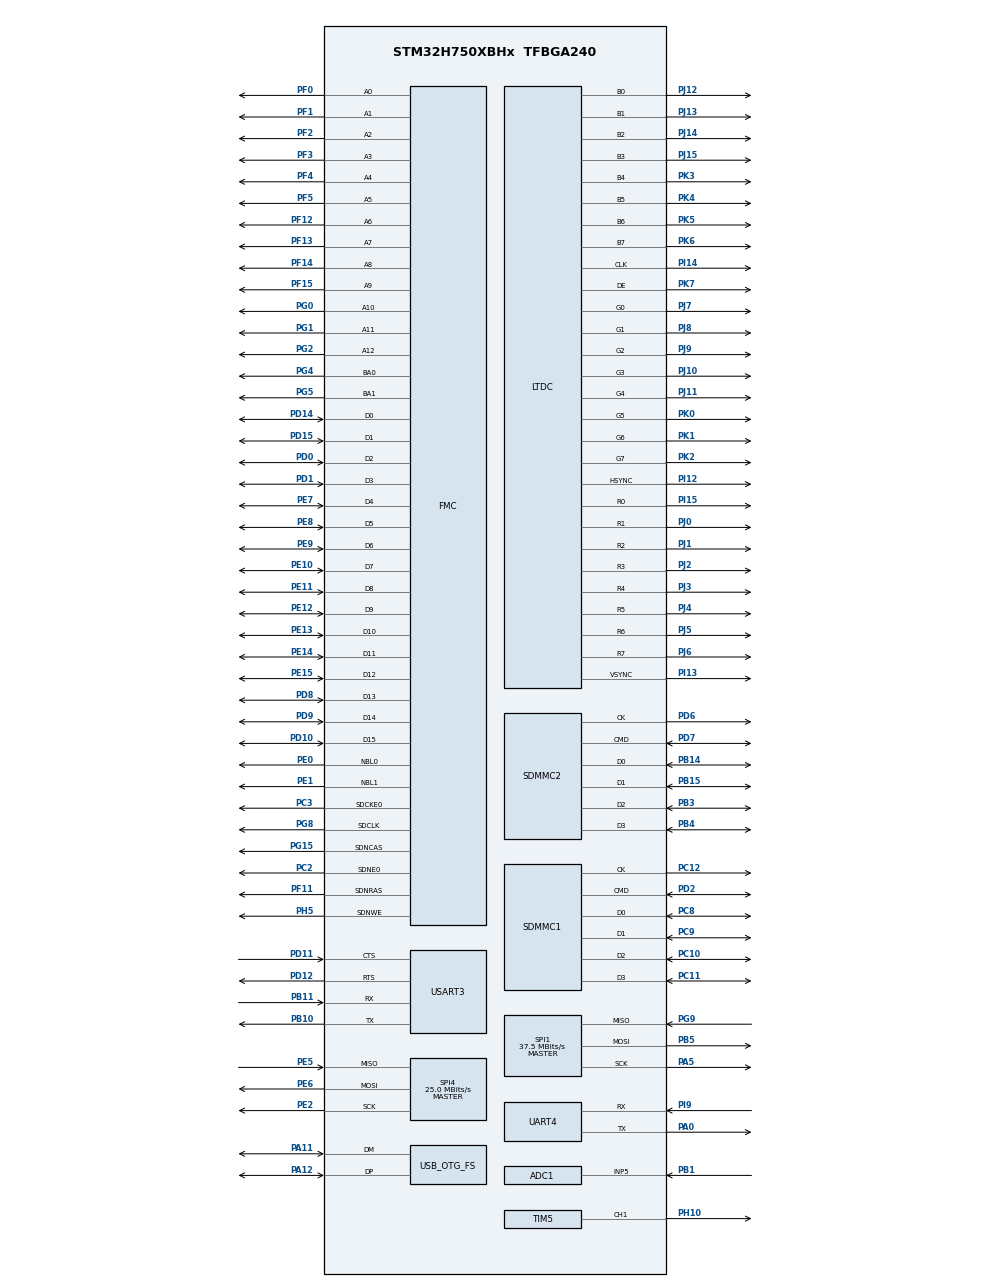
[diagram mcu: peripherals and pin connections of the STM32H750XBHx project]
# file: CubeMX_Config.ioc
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ADC1.Channel-0\#ChannelRegularConversion=ADC_CHANNEL_5
ADC1.NbrOfConversionFlag=1
ADC1.OffsetNumber-0\#ChannelRegularConversion=ADC_OFFSET_NONE
ADC1.OffsetSignedSaturation-0\#ChannelRegularConversion=DISABLE
ADC1.Rank-0\#ChannelRegularConversion=1
ADC1.SamplingTime-0\#ChannelRegularConversion=ADC_SAMPLETIME_1CYCLE_5
ADC1.master=1
Mcu.Family=STM32H7
Mcu.Name=STM32H750XBHx
Mcu.Package=TFBGA240
NVIC.OTG_FS_IRQn=true\:0\:0\:false\:false\:true\:true\:true\:true
NVIC.PriorityGroup=NVIC_PRIORITYGROUP_4
NVIC.SDMMC1_IRQn=true\:0\:0\:false\:false\:true\:true\:true\:true
NVIC.SDMMC2_IRQn=true\:0\:0\:false\:false\:true\:true\:true\:true
PA0.Mode=Asynchronous
PA0.Signal=UART4_TX
PA11.GPIO_Speed=GPIO_SPEED_FREQ_VERY_HIGH
PA11.Mode=Device_Only
PA11.Signal=USB_OTG_FS_DM
PA12.GPIO_Speed=GPIO_SPEED_FREQ_VERY_HIGH
PA12.Mode=Device_Only
PA12.Signal=USB_OTG_FS_DP
PA5.GPIO_Speed=GPIO_SPEED_FREQ_HIGH
PA5.Mode=Full_Duplex_Master
PA5.Signal=SPI1_SCK
PB1.Signal=ADCx_INP5
PB10.Mode=Asynchronous
PB10.Signal=USART3_TX
PB11.Mode=Asynchronous
PB11.Signal=USART3_RX
PB14.Mode=SD_4_bits_Wide_bus
PB14.Signal=SDMMC2_D0
PB15.Mode=SD_4_bits_Wide_bus
PB15.Signal=SDMMC2_D1
PB3\ (JTDO/TRACESWO).Mode=SD_4_bits_Wide_bus
PB3\ (JTDO/TRACESWO).Signal=SDMMC2_D2
PB4\ (NJTRST).Mode=SD_4_bits_Wide_bus
PB4\ (NJTRST).Signal=SDMMC2_D3
PB5.GPIO_Speed=GPIO_SPEED_FREQ_HIGH
PB5.Mode=Full_Duplex_Master
PB5.Signal=SPI1_MOSI
PC10.Mode=SD_4_bits_Wide_bus
PC10.Signal=SDMMC1_D2
PC11.Mode=SD_4_bits_Wide_bus
PC11.Signal=SDMMC1_D3
PC12.Mode=SD_4_bits_Wide_bus
PC12.Signal=SDMMC1_CK
PC2.GPIO_Speed_High_Default=GPIO_SPEED_FREQ_VERY_HIGH
PC2.Mode=SdramChipSelect1_1
PC2.Signal=FMC_SDNE0
PC3.GPIO_Speed_High_Default=GPIO_SPEED_FREQ_VERY_HIGH
PC3.Mode=SdramChipSelect1_1
PC3.Signal=FMC_SDCKE0
PC8.Mode=SD_4_bits_Wide_bus
PC8.Signal=SDMMC1_D0
PC9.Mode=SD_4_bits_Wide_bus
PC9.Signal=SDMMC1_D1
PD0.GPIO_Speed_High_Default=GPIO_SPEED_FREQ_VERY_HIGH
PD0.Signal=FMC_D2_DA2
PD1.GPIO_Speed_High_Default=GPIO_SPEED_FREQ_VERY_HIGH
PD1.Signal=FMC_D3_DA3
PD10.GPIO_Speed_High_Default=GPIO_SPEED_FREQ_VERY_HIGH
PD10.Signal=FMC_D15_DA15
PD11.Mode=CTS_RTS
PD11.Signal=USART3_CTS
PD12.Mode=CTS_RTS
PD12.Signal=USART3_RTS
PD14.GPIO_Speed_High_Default=GPIO_SPEED_FREQ_VERY_HIGH
PD14.Signal=FMC_D0_DA0
PD15.GPIO_Speed_High_Default=GPIO_SPEED_FREQ_VERY_HIGH
PD15.Signal=FMC_D1_DA1
PD2.Mode=SD_4_bits_Wide_bus
PD2.Signal=SDMMC1_CMD
PD6.Mode=SD_4_bits_Wide_bus
PD6.Signal=SDMMC2_CK
PD7.Mode=SD_4_bits_Wide_bus
PD7.Signal=SDMMC2_CMD
PD8.GPIO_Speed_High_Default=GPIO_SPEED_FREQ_VERY_HIGH
PD8.Signal=FMC_D13_DA13
PD9.GPIO_Speed_High_Default=GPIO_SPEED_FREQ_VERY_HIGH
PD9.Signal=FMC_D14_DA14
PE0.GPIO_Speed_High_Default=GPIO_SPEED_FREQ_VERY_HIGH
PE0.Signal=FMC_NBL0
PE1.GPIO_Speed_High_Default=GPIO_SPEED_FREQ_VERY_HIGH
PE1.Signal=FMC_NBL1
PE10.GPIO_Speed_High_Default=GPIO_SPEED_FREQ_VERY_HIGH
PE10.Signal=FMC_D7_DA7
PE11.GPIO_Speed_High_Default=GPIO_SPEED_FREQ_VERY_HIGH
PE11.Signal=FMC_D8_DA8
PE12.GPIO_Speed_High_Default=GPIO_SPEED_FREQ_VERY_HIGH
PE12.Signal=FMC_D9_DA9
PE13.GPIO_Speed_High_Default=GPIO_SPEED_FREQ_VERY_HIGH
PE13.Signal=FMC_D10_DA10
PE14.GPIO_Speed_High_Default=GPIO_SPEED_FREQ_VERY_HIGH
PE14.Signal=FMC_D11_DA11
PE15.GPIO_Speed_High_Default=GPIO_SPEED_FREQ_VERY_HIGH
PE15.Signal=FMC_D12_DA12
PE2.GPIO_Speed=GPIO_SPEED_FREQ_HIGH
PE2.Mode=Full_Duplex_Master
PE2.Signal=SPI4_SCK
PE5.GPIO_Speed=GPIO_SPEED_FREQ_HIGH
PE5.Mode=Full_Duplex_Master
PE5.Signal=SPI4_MISO
PE6.GPIO_Speed=GPIO_SPEED_FREQ_HIGH
PE6.Mode=Full_Duplex_Master
PE6.Signal=SPI4_MOSI
PE7.GPIO_Speed_High_Default=GPIO_SPEED_FREQ_VERY_HIGH
PE7.Signal=FMC_D4_DA4
PE8.GPIO_Speed_High_Default=GPIO_SPEED_FREQ_VERY_HIGH
PE8.Signal=FMC_D5_DA5
PE9.GPIO_Speed_High_Default=GPIO_SPEED_FREQ_VERY_HIGH
PE9.Signal=FMC_D6_DA6
PF0.GPIO_Speed_High_Default=GPIO_SPEED_FREQ_VERY_HIGH
PF0.Signal=FMC_A0
PF1.GPIO_Speed_High_Default=GPIO_SPEED_FREQ_VERY_HIGH
PF1.Signal=FMC_A1
PF11.GPIO_Speed_High_Default=GPIO_SPEED_FREQ_VERY_HIGH
PF11.Signal=FMC_SDNRAS
PF12.GPIO_Speed_High_Default=GPIO_SPEED_FREQ_VERY_HIGH
PF12.Signal=FMC_A6
PF13.GPIO_Speed_High_Default=GPIO_SPEED_FREQ_VERY_HIGH
PF13.Signal=FMC_A7
PF14.GPIO_Speed_High_Default=GPIO_SPEED_FREQ_VERY_HIGH
PF14.Signal=FMC_A8
PF15.GPIO_Speed_High_Default=GPIO_SPEED_FREQ_VERY_HIGH
PF15.Signal=FMC_A9
PF2.GPIO_Speed_High_Default=GPIO_SPEED_FREQ_VERY_HIGH
PF2.Signal=FMC_A2
PF3.GPIO_Speed_High_Default=GPIO_SPEED_FREQ_VERY_HIGH
PF3.Signal=FMC_A3
PF4.GPIO_Speed_High_Default=GPIO_SPEED_FREQ_VERY_HIGH
PF4.Signal=FMC_A4
PF5.GPIO_Speed_High_Default=GPIO_SPEED_FREQ_VERY_HIGH
PF5.Signal=FMC_A5
PG0.GPIO_Speed_High_Default=GPIO_SPEED_FREQ_VERY_HIGH
PG0.Signal=FMC_A10
PG1.GPIO_Speed_High_Default=GPIO_SPEED_FREQ_VERY_HIGH
PG1.Signal=FMC_A11
PG11.GPIO_Speed=GPIO_SPEED_FREQ_VERY_HIGH
PG11.Signal=ETH_TX_EN
PG14.GPIO_Speed=GPIO_SPEED_FREQ_VERY_HIGH
PG14.Signal=ETH_TXD1
PG15.GPIO_Speed_High_Default=GPIO_SPEED_FREQ_VERY_HIGH
PG15.Signal=FMC_SDNCAS
PG2.GPIO_Speed_High_Default=GPIO_SPEED_FREQ_VERY_HIGH
PG2.Signal=FMC_A12
PG4.GPIO_Speed_High_Default=GPIO_SPEED_FREQ_VERY_HIGH
PG4.Signal=FMC_A14_BA0
PG5.GPIO_Speed_High_Default=GPIO_SPEED_FREQ_VERY_HIGH
PG5.Signal=FMC_A15_BA1
PG8.GPIO_Speed_High_Default=GPIO_SPEED_FREQ_VERY_HIGH
PG8.Signal=FMC_SDCLK
PG9.GPIO_Speed=GPIO_SPEED_FREQ_HIGH
PG9.Mode=Full_Duplex_Master
PG9.Signal=SPI1_MISO
PH0-OSC_IN\ (PH0).Mode=HSE-External-Oscillator
PH0-OSC_IN\ (PH0).Signal=RCC_OSC_IN
PH1-OSC_OUT\ (PH1).Mode=HSE-External-Oscillator
PH1-OSC_OUT\ (PH1).Signal=RCC_OSC_OUT
PH10.Signal=S_TIM5_CH1
PH5.GPIO_Speed_High_Default=GPIO_SPEED_FREQ_VERY_HIGH
PH5.Signal=FMC_SDNWE
PI12.GPIO_Speed=GPIO_SPEED_FREQ_VERY_HIGH
PI12.Mode=RGB888
PI12.Signal=LTDC_HSYNC
PI13.GPIO_Speed=GPIO_SPEED_FREQ_VERY_HIGH
PI13.Mode=RGB888
PI13.Signal=LTDC_VSYNC
PI14.GPIO_Speed=GPIO_SPEED_FREQ_VERY_HIGH
PI14.Mode=RGB888
PI14.Signal=LTDC_CLK
PI15.GPIO_Speed=GPIO_SPEED_FREQ_VERY_HIGH
PI15.Mode=RGB888
PI15.Signal=LTDC_R0
PI9.Mode=Asynchronous
PI9.Signal=UART4_RX
PJ0.GPIO_Speed=GPIO_SPEED_FREQ_VERY_HIGH
PJ0.Mode=RGB888
PJ0.Signal=LTDC_R1
PJ1.GPIO_Speed=GPIO_SPEED_FREQ_VERY_HIGH
PJ1.Mode=RGB888
PJ1.Signal=LTDC_R2
PJ10.GPIO_Speed=GPIO_SPEED_FREQ_VERY_HIGH
PJ10.Mode=RGB888
PJ10.Signal=LTDC_G3
PJ11.GPIO_Speed=GPIO_SPEED_FREQ_VERY_HIGH
PJ11.Mode=RGB888
PJ11.Signal=LTDC_G4
PJ12.GPIO_Speed=GPIO_SPEED_FREQ_VERY_HIGH
PJ12.Mode=RGB888
PJ12.Signal=LTDC_B0
PJ13.GPIO_Speed=GPIO_SPEED_FREQ_VERY_HIGH
PJ13.Mode=RGB888
PJ13.Signal=LTDC_B1
PJ14.GPIO_Speed=GPIO_SPEED_FREQ_VERY_HIGH
PJ14.Mode=RGB888
PJ14.Signal=LTDC_B2
PJ15.GPIO_Speed=GPIO_SPEED_FREQ_VERY_HIGH
PJ15.Mode=RGB888
PJ15.Signal=LTDC_B3
PJ2.GPIO_Speed=GPIO_SPEED_FREQ_VERY_HIGH
PJ2.Mode=RGB888
PJ2.Signal=LTDC_R3
PJ3.GPIO_Speed=GPIO_SPEED_FREQ_VERY_HIGH
PJ3.Mode=RGB888
PJ3.Signal=LTDC_R4
PJ4.GPIO_Speed=GPIO_SPEED_FREQ_VERY_HIGH
PJ4.Mode=RGB888
PJ4.Signal=LTDC_R5
PJ5.GPIO_Speed=GPIO_SPEED_FREQ_VERY_HIGH
PJ5.Mode=RGB888
PJ5.Signal=LTDC_R6
PJ6.GPIO_Speed=GPIO_SPEED_FREQ_VERY_HIGH
PJ6.Mode=RGB888
PJ6.Signal=LTDC_R7
PJ7.GPIO_Speed=GPIO_SPEED_FREQ_VERY_HIGH
PJ7.Mode=RGB888
PJ7.Signal=LTDC_G0
PJ8.GPIO_Speed=GPIO_SPEED_FREQ_VERY_HIGH
PJ8.Mode=RGB888
PJ8.Signal=LTDC_G1
PJ9.GPIO_Speed=GPIO_SPEED_FREQ_VERY_HIGH
PJ9.Mode=RGB888
PJ9.Signal=LTDC_G2
PK0.GPIO_Speed=GPIO_SPEED_FREQ_VERY_HIGH
PK0.Mode=RGB888
PK0.Signal=LTDC_G5
PK1.GPIO_Speed=GPIO_SPEED_FREQ_VERY_HIGH
PK1.Mode=RGB888
PK1.Signal=LTDC_G6
PK2.GPIO_Speed=GPIO_SPEED_FREQ_VERY_HIGH
PK2.Mode=RGB888
PK2.Signal=LTDC_G7
PK3.GPIO_Speed=GPIO_SPEED_FREQ_VERY_HIGH
PK3.Mode=RGB888
PK3.Signal=LTDC_B4
PK4.GPIO_Speed=GPIO_SPEED_FREQ_VERY_HIGH
PK4.Mode=RGB888
PK4.Signal=LTDC_B5
PK5.GPIO_Speed=GPIO_SPEED_FREQ_VERY_HIGH
PK5.Mode=RGB888
PK5.Signal=LTDC_B6
PK6.GPIO_Speed=GPIO_SPEED_FREQ_VERY_HIGH
PK6.Mode=RGB888
PK6.Signal=LTDC_B7
PK7.GPIO_Speed=GPIO_SPEED_FREQ_VERY_HIGH
PK7.Mode=RGB888
PK7.Signal=LTDC_DE
ProjectManager.HeapSize=0x200
ProjectManager.StackSize=0x400
ProjectManager.TargetToolchain=Makefile
RCC.ADCFreq_Value=75000000
RCC.APB1Freq_Value=18750000
RCC.APB2Freq_Value=18750000
RCC.APB3Freq_Value=18750000
RCC.APB4Freq_Value=18750000
RCC.CortexFreq_Value=75000000
RCC.D1PPRE=RCC_APB3_DIV2
RCC.D2PPRE1=RCC_APB1_DIV2
RCC.D2PPRE2=RCC_APB2_DIV2
RCC.D3PPRE=RCC_APB4_DIV2
RCC.DIVM1=2
RCC.DIVM2=2
RCC.DIVM3=2
RCC.DIVN1=12
RCC.DIVN2=12
RCC.DIVN3=12
RCC.DIVP3=8
RCC.DIVQ3=3
RCC.DIVR3=3
RCC.FMCCLockSelection=RCC_FMCCLKSOURCE_PLL2
RCC.HCLKFreq_Value=37500000
RCC.HPRE=RCC_HCLK_DIV2
RCC.LPTIM1CLockSelection=RCC_LPTIM1CLKSOURCE_LSI
RCC.PLL2FRACN=0
RCC.PLL3FRACN=0
RCC.PLLFRACN=0
RCC.PLLSourceVirtual=RCC_PLLSOURCE_HSE
RCC.SDMMC1CLockSelection=RCC_SDMMCCLKSOURCE_PLL2
RCC.SPI123CLockSelection=RCC_SPI123CLKSOURCE_PLL2
RCC.SYSCLKFreq_VALUE=75000000
RCC.SYSCLKSource=RCC_SYSCLKSOURCE_PLLCLK
RCC.Spi45ClockSelection=RCC_SPI45CLKSOURCE_PLL3
RCC.USBCLockSelection=RCC_USBCLKSOURCE_HSI48
RCC.USBFreq_Value=48000000
SH.ADCx_INP5.0=ADC1_INP5,IN5-Single-Ended
SH.FMC_A0.0=FMC_A0,13b-sda1
SH.FMC_A1.0=FMC_A1,13b-sda1
SH.FMC_A10.0=FMC_A10,13b-sda1
SH.FMC_A11.0=FMC_A11,13b-sda1
SH.FMC_A12.0=FMC_A12,13b-sda1
SH.FMC_A14_BA0.0=FMC_BA0,FourSdramBanks1
SH.FMC_A15_BA1.0=FMC_BA1,FourSdramBanks1
SH.FMC_A2.0=FMC_A2,13b-sda1
SH.FMC_A3.0=FMC_A3,13b-sda1
SH.FMC_A4.0=FMC_A4,13b-sda1
SH.FMC_A5.0=FMC_A5,13b-sda1
SH.FMC_A6.0=FMC_A6,13b-sda1
SH.FMC_A7.0=FMC_A7,13b-sda1
SH.FMC_A8.0=FMC_A8,13b-sda1
SH.FMC_A9.0=FMC_A9,13b-sda1
SH.FMC_D0_DA0.0=FMC_D0,sd-16b-d1
SH.FMC_D10_DA10.0=FMC_D10,sd-16b-d1
SH.FMC_D11_DA11.0=FMC_D11,sd-16b-d1
SH.FMC_D12_DA12.0=FMC_D12,sd-16b-d1
SH.FMC_D13_DA13.0=FMC_D13,sd-16b-d1
SH.FMC_D14_DA14.0=FMC_D14,sd-16b-d1
SH.FMC_D15_DA15.0=FMC_D15,sd-16b-d1
SH.FMC_D1_DA1.0=FMC_D1,sd-16b-d1
SH.FMC_D2_DA2.0=FMC_D2,sd-16b-d1
SH.FMC_D3_DA3.0=FMC_D3,sd-16b-d1
SH.FMC_D4_DA4.0=FMC_D4,sd-16b-d1
SH.FMC_D5_DA5.0=FMC_D5,sd-16b-d1
SH.FMC_D6_DA6.0=FMC_D6,sd-16b-d1
SH.FMC_D7_DA7.0=FMC_D7,sd-16b-d1
SH.FMC_D8_DA8.0=FMC_D8,sd-16b-d1
SH.FMC_D9_DA9.0=FMC_D9,sd-16b-d1
SH.FMC_NBL0.0=FMC_NBL0,Sd2ByteEnable1
SH.FMC_NBL1.0=FMC_NBL1,Sd2ByteEnable1
SH.FMC_SDCLK.0=FMC_SDCLK,13b-sda1
SH.FMC_SDNCAS.0=FMC_SDNCAS,13b-sda1
SH.FMC_SDNRAS.0=FMC_SDNRAS,13b-sda1
SH.FMC_SDNWE.0=FMC_SDNWE,13b-sda1
SH.S_TIM5_CH1.0=TIM5_CH1,PWM Generation1 CH1
SPI1.BaudRatePrescaler=SPI_BAUDRATEPRESCALER_2
SPI1.CalculateBaudRate=37.5 MBits/s
SPI1.Direction=SPI_DIRECTION_2LINES
SPI1.Mode=SPI_MODE_MASTER
SPI1.VirtualType=VM_MASTER
SPI4.BaudRatePrescaler=SPI_BAUDRATEPRESCALER_2
SPI4.CalculateBaudRate=25.0 MBits/s
SPI4.Direction=SPI_DIRECTION_2LINES
SPI4.Mode=SPI_MODE_MASTER
SPI4.VirtualType=VM_MASTER
TIM5.Channel-PWM\ Generation1\ CH1=TIM_CHANNEL_1
USART3.VirtualMode-Asynchronous=VM_ASYNC
USB_OTG_FS.VirtualMode=Device_Only
VP_LPTIM1_VS_LPTIM_counterModeInternalClock.Mode=Counts__internal_clock_event_00
board=custom

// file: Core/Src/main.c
/* USER CODE BEGIN Header */
/**
  ******************************************************************************
  * @file           : main.c
  * @brief          : Main program body
  ******************************************************************************
  * @attention
  *
  * <h2><center>&copy; Copyright (c) 2020 STMicroelectronics.
  * All rights reserved.</center></h2>
  *
  * This software component is licensed by ST under BSD 3-Clause license,
  * the "License"; You may not use this file except in compliance with the
  * License. You may obtain a copy of the License at:
  *                        opensource.org/licenses/BSD-3-Clause
  *
  ******************************************************************************
  */
/* USER CODE END Header */
#include "main.h"

 ADC_HandleTypeDef hadc1;

LPTIM_HandleTypeDef hlptim1;

LTDC_HandleTypeDef hltdc;

SD_HandleTypeDef hsd1;
SD_HandleTypeDef hsd2;

SPI_HandleTypeDef hspi1;
SPI_HandleTypeDef hspi4;

TIM_HandleTypeDef htim5;

UART_HandleTypeDef huart4;
UART_HandleTypeDef huart3;

PCD_HandleTypeDef hpcd_USB_OTG_FS;

SDRAM_HandleTypeDef hsdram1;

void SystemClock_Config(void);
void PeriphCommonClock_Config(void);
static void MX_GPIO_Init(void);
static void MX_FMC_Init(void);
static void MX_LTDC_Init(void);
static void MX_SDMMC1_SD_Init(void);
static void MX_SDMMC2_SD_Init(void);
static void MX_SPI4_Init(void);
static void MX_UART4_Init(void);
static void MX_SPI1_Init(void);
static void MX_USART3_UART_Init(void);
static void MX_USB_OTG_FS_PCD_Init(void);
static void MX_ADC1_Init(void);
static void MX_TIM5_Init(void);
static void MX_LPTIM1_Init(void);

int main(void)
{

  /* MCU Configuration--------------------------------------------------------*/

// We load this binary into ram and do not perform init
# if 0

  /* Reset of all peripherals, Initializes the Flash interface and the Systick. */
  HAL_Init();

  /* Configure the system clock */
  SystemClock_Config();

/* Configure the peripherals common clocks */
  PeriphCommonClock_Config();

  /* Initialize all configured peripherals */
  MX_GPIO_Init();
  MX_FMC_Init();
  MX_LTDC_Init();
  MX_SDMMC1_SD_Init();
  MX_SDMMC2_SD_Init();
  MX_SPI4_Init();
  MX_UART4_Init();
  MX_SPI1_Init();
  MX_USART3_UART_Init();
  //MX_USB_OTG_FS_PCD_Init();
  MX_ADC1_Init();
  MX_TIM5_Init();
  //MX_LPTIM1_Init();
  /* USER CODE BEGIN 2 */
#endif
  /* USER CODE END 2 */

  /* Infinite loop */
  while (1)
  {

    /* USER CODE BEGIN 3 */

#if 1
    uint8_t Test[] = "Hello World !!!\r\n"; //Data to send
    HAL_UART_Transmit(&huart4,Test,sizeof(Test),10);// Sending in normal mode
    HAL_Delay(1000);    /* USER CODE BEGIN 3 */
#endif

  }
  /* USER CODE END 3 */
}

void SystemClock_Config(void)
{
  RCC_OscInitTypeDef RCC_OscInitStruct = {0};
  RCC_ClkInitTypeDef RCC_ClkInitStruct = {0};

  /** Supply configuration update enable
  */
  HAL_PWREx_ConfigSupply(PWR_LDO_SUPPLY);

  /** Configure the main internal regulator output voltage
  */
  __HAL_PWR_VOLTAGESCALING_CONFIG(PWR_REGULATOR_VOLTAGE_SCALE3);

  while(!__HAL_PWR_GET_FLAG(PWR_FLAG_VOSRDY)) {}

  /** Macro to configure the PLL clock source
  */
  __HAL_RCC_PLL_PLLSOURCE_CONFIG(RCC_PLLSOURCE_HSE);

  /** Initializes the RCC Oscillators according to the specified parameters
  * in the RCC_OscInitTypeDef structure.
  */
  RCC_OscInitStruct.OscillatorType = RCC_OSCILLATORTYPE_HSI48|RCC_OSCILLATORTYPE_LSI
                              |RCC_OSCILLATORTYPE_HSE;
  RCC_OscInitStruct.HSEState = RCC_HSE_ON;
  RCC_OscInitStruct.LSIState = RCC_LSI_ON;
  RCC_OscInitStruct.HSI48State = RCC_HSI48_ON;
  RCC_OscInitStruct.PLL.PLLState = RCC_PLL_ON;
  RCC_OscInitStruct.PLL.PLLSource = RCC_PLLSOURCE_HSE;
  RCC_OscInitStruct.PLL.PLLM = 2;
  RCC_OscInitStruct.PLL.PLLN = 12;
  RCC_OscInitStruct.PLL.PLLP = 2;
  RCC_OscInitStruct.PLL.PLLQ = 2;
  RCC_OscInitStruct.PLL.PLLR = 2;
  RCC_OscInitStruct.PLL.PLLRGE = RCC_PLL1VCIRANGE_3;
  RCC_OscInitStruct.PLL.PLLVCOSEL = RCC_PLL1VCOMEDIUM;
  RCC_OscInitStruct.PLL.PLLFRACN = 0;
  if (HAL_RCC_OscConfig(&RCC_OscInitStruct) != HAL_OK)
  {
    Error_Handler();
  }

  /** Initializes the CPU, AHB and APB buses clocks
  */
  RCC_ClkInitStruct.ClockType = RCC_CLOCKTYPE_HCLK|RCC_CLOCKTYPE_SYSCLK
                              |RCC_CLOCKTYPE_PCLK1|RCC_CLOCKTYPE_PCLK2
                              |RCC_CLOCKTYPE_D3PCLK1|RCC_CLOCKTYPE_D1PCLK1;
  RCC_ClkInitStruct.SYSCLKSource = RCC_SYSCLKSOURCE_PLLCLK;
  RCC_ClkInitStruct.SYSCLKDivider = RCC_SYSCLK_DIV1;
  RCC_ClkInitStruct.AHBCLKDivider = RCC_HCLK_DIV2;
  RCC_ClkInitStruct.APB3CLKDivider = RCC_APB3_DIV2;
  RCC_ClkInitStruct.APB1CLKDivider = RCC_APB1_DIV2;
  RCC_ClkInitStruct.APB2CLKDivider = RCC_APB2_DIV2;
  RCC_ClkInitStruct.APB4CLKDivider = RCC_APB4_DIV2;

  if (HAL_RCC_ClockConfig(&RCC_ClkInitStruct, FLASH_LATENCY_0) != HAL_OK)
  {
    Error_Handler();
  }
}

void PeriphCommonClock_Config(void)
{
  RCC_PeriphCLKInitTypeDef PeriphClkInitStruct = {0};

  /** Initializes the peripherals clock
  */
  PeriphClkInitStruct.PeriphClockSelection = RCC_PERIPHCLK_FMC|RCC_PERIPHCLK_SDMMC
                              |RCC_PERIPHCLK_SPI1|RCC_PERIPHCLK_SPI4
                              |RCC_PERIPHCLK_LTDC;
  PeriphClkInitStruct.PLL2.PLL2M = 2;
  PeriphClkInitStruct.PLL2.PLL2N = 12;
  PeriphClkInitStruct.PLL2.PLL2P = 2;
  PeriphClkInitStruct.PLL2.PLL2Q = 2;
  PeriphClkInitStruct.PLL2.PLL2R = 2;
  PeriphClkInitStruct.PLL2.PLL2RGE = RCC_PLL2VCIRANGE_3;
  PeriphClkInitStruct.PLL2.PLL2VCOSEL = RCC_PLL2VCOMEDIUM;
  PeriphClkInitStruct.PLL2.PLL2FRACN = 0;
  PeriphClkInitStruct.PLL3.PLL3M = 2;
  PeriphClkInitStruct.PLL3.PLL3N = 12;
  PeriphClkInitStruct.PLL3.PLL3P = 8;
  PeriphClkInitStruct.PLL3.PLL3Q = 3;
  PeriphClkInitStruct.PLL3.PLL3R = 3;
  PeriphClkInitStruct.PLL3.PLL3RGE = RCC_PLL3VCIRANGE_3;
  PeriphClkInitStruct.PLL3.PLL3VCOSEL = RCC_PLL3VCOMEDIUM;
  PeriphClkInitStruct.PLL3.PLL3FRACN = 0;
  PeriphClkInitStruct.FmcClockSelection = RCC_FMCCLKSOURCE_PLL2;
  PeriphClkInitStruct.SdmmcClockSelection = RCC_SDMMCCLKSOURCE_PLL2;
  PeriphClkInitStruct.Spi123ClockSelection = RCC_SPI123CLKSOURCE_PLL2;
  PeriphClkInitStruct.Spi45ClockSelection = RCC_SPI45CLKSOURCE_PLL3;
  if (HAL_RCCEx_PeriphCLKConfig(&PeriphClkInitStruct) != HAL_OK)
  {
    Error_Handler();
  }
}

static void MX_ADC1_Init(void)
{

  ADC_MultiModeTypeDef multimode = {0};
  ADC_ChannelConfTypeDef sConfig = {0};

  /** Common config
  */
  hadc1.Instance = ADC1;
  hadc1.Init.Resolution = ADC_RESOLUTION_16B;
  hadc1.Init.ScanConvMode = ADC_SCAN_DISABLE;
  hadc1.Init.EOCSelection = ADC_EOC_SINGLE_CONV;
  hadc1.Init.LowPowerAutoWait = DISABLE;
  hadc1.Init.ContinuousConvMode = DISABLE;
  hadc1.Init.NbrOfConversion = 1;
  hadc1.Init.DiscontinuousConvMode = DISABLE;
  hadc1.Init.ExternalTrigConv = ADC_SOFTWARE_START;
  hadc1.Init.ExternalTrigConvEdge = ADC_EXTERNALTRIGCONVEDGE_NONE;
  hadc1.Init.ConversionDataManagement = ADC_CONVERSIONDATA_DR;
  hadc1.Init.Overrun = ADC_OVR_DATA_PRESERVED;
  hadc1.Init.LeftBitShift = ADC_LEFTBITSHIFT_NONE;
  hadc1.Init.OversamplingMode = DISABLE;
  if (HAL_ADC_Init(&hadc1) != HAL_OK)
  {
    Error_Handler();
  }

  /** Configure the ADC multi-mode
  */
  multimode.Mode = ADC_MODE_INDEPENDENT;
  if (HAL_ADCEx_MultiModeConfigChannel(&hadc1, &multimode) != HAL_OK)
  {
    Error_Handler();
  }

  /** Configure Regular Channel
  */
  sConfig.Channel = ADC_CHANNEL_5;
  sConfig.Rank = ADC_REGULAR_RANK_1;
  sConfig.SamplingTime = ADC_SAMPLETIME_1CYCLE_5;
  sConfig.SingleDiff = ADC_SINGLE_ENDED;
  sConfig.OffsetNumber = ADC_OFFSET_NONE;
  sConfig.Offset = 0;
  sConfig.OffsetSignedSaturation = DISABLE;
  if (HAL_ADC_ConfigChannel(&hadc1, &sConfig) != HAL_OK)
  {
    Error_Handler();
  }

}

static void MX_LPTIM1_Init(void)
{

  hlptim1.Instance = LPTIM1;
  hlptim1.Init.Clock.Source = LPTIM_CLOCKSOURCE_APBCLOCK_LPOSC;
  hlptim1.Init.Clock.Prescaler = LPTIM_PRESCALER_DIV1;
  hlptim1.Init.Trigger.Source = LPTIM_TRIGSOURCE_SOFTWARE;
  hlptim1.Init.OutputPolarity = LPTIM_OUTPUTPOLARITY_HIGH;
  hlptim1.Init.UpdateMode = LPTIM_UPDATE_IMMEDIATE;
  hlptim1.Init.CounterSource = LPTIM_COUNTERSOURCE_INTERNAL;
  hlptim1.Init.Input1Source = LPTIM_INPUT1SOURCE_GPIO;
  hlptim1.Init.Input2Source = LPTIM_INPUT2SOURCE_GPIO;
  if (HAL_LPTIM_Init(&hlptim1) != HAL_OK)
  {
    Error_Handler();
  }

}

static void MX_LTDC_Init(void)
{

  LTDC_LayerCfgTypeDef pLayerCfg = {0};
  LTDC_LayerCfgTypeDef pLayerCfg1 = {0};

  hltdc.Instance = LTDC;
  hltdc.Init.HSPolarity = LTDC_HSPOLARITY_AL;
  hltdc.Init.VSPolarity = LTDC_VSPOLARITY_AL;
  hltdc.Init.DEPolarity = LTDC_DEPOLARITY_AL;
  hltdc.Init.PCPolarity = LTDC_PCPOLARITY_IPC;
  hltdc.Init.HorizontalSync = 7;
  hltdc.Init.VerticalSync = 3;
  hltdc.Init.AccumulatedHBP = 14;
  hltdc.Init.AccumulatedVBP = 5;
  hltdc.Init.AccumulatedActiveW = 654;
  hltdc.Init.AccumulatedActiveH = 485;
  hltdc.Init.TotalWidth = 660;
  hltdc.Init.TotalHeigh = 487;
  hltdc.Init.Backcolor.Blue = 0;
  hltdc.Init.Backcolor.Green = 0;
  hltdc.Init.Backcolor.Red = 0;
  if (HAL_LTDC_Init(&hltdc) != HAL_OK)
  {
    Error_Handler();
  }
  pLayerCfg.WindowX0 = 0;
  pLayerCfg.WindowX1 = 0;
  pLayerCfg.WindowY0 = 0;
  pLayerCfg.WindowY1 = 0;
  pLayerCfg.PixelFormat = LTDC_PIXEL_FORMAT_ARGB8888;
  pLayerCfg.Alpha = 0;
  pLayerCfg.Alpha0 = 0;
  pLayerCfg.BlendingFactor1 = LTDC_BLENDING_FACTOR1_CA;
  pLayerCfg.BlendingFactor2 = LTDC_BLENDING_FACTOR2_CA;
  pLayerCfg.FBStartAdress = 0;
  pLayerCfg.ImageWidth = 0;
  pLayerCfg.ImageHeight = 0;
  pLayerCfg.Backcolor.Blue = 0;
  pLayerCfg.Backcolor.Green = 0;
  pLayerCfg.Backcolor.Red = 0;
  if (HAL_LTDC_ConfigLayer(&hltdc, &pLayerCfg, 0) != HAL_OK)
  {
    Error_Handler();
  }
  pLayerCfg1.WindowX0 = 0;
  pLayerCfg1.WindowX1 = 0;
  pLayerCfg1.WindowY0 = 0;
  pLayerCfg1.WindowY1 = 0;
  pLayerCfg1.PixelFormat = LTDC_PIXEL_FORMAT_ARGB8888;
  pLayerCfg1.Alpha = 0;
  pLayerCfg1.Alpha0 = 0;
  pLayerCfg1.BlendingFactor1 = LTDC_BLENDING_FACTOR1_CA;
  pLayerCfg1.BlendingFactor2 = LTDC_BLENDING_FACTOR2_CA;
  pLayerCfg1.FBStartAdress = 0;
  pLayerCfg1.ImageWidth = 0;
  pLayerCfg1.ImageHeight = 0;
  pLayerCfg1.Backcolor.Blue = 0;
  pLayerCfg1.Backcolor.Green = 0;
  pLayerCfg1.Backcolor.Red = 0;
  if (HAL_LTDC_ConfigLayer(&hltdc, &pLayerCfg1, 1) != HAL_OK)
  {
    Error_Handler();
  }

}

static void MX_SDMMC1_SD_Init(void)
{

  hsd1.Instance = SDMMC1;
  hsd1.Init.ClockEdge = SDMMC_CLOCK_EDGE_RISING;
  hsd1.Init.ClockPowerSave = SDMMC_CLOCK_POWER_SAVE_DISABLE;
  hsd1.Init.BusWide = SDMMC_BUS_WIDE_4B;
  hsd1.Init.HardwareFlowControl = SDMMC_HARDWARE_FLOW_CONTROL_DISABLE;
  hsd1.Init.ClockDiv = 0;
  if (HAL_SD_Init(&hsd1) != HAL_OK)
  {
    Error_Handler();
  }

}

static void MX_SDMMC2_SD_Init(void)
{

  hsd2.Instance = SDMMC2;
  hsd2.Init.ClockEdge = SDMMC_CLOCK_EDGE_RISING;
  hsd2.Init.ClockPowerSave = SDMMC_CLOCK_POWER_SAVE_DISABLE;
  hsd2.Init.BusWide = SDMMC_BUS_WIDE_4B;
  hsd2.Init.HardwareFlowControl = SDMMC_HARDWARE_FLOW_CONTROL_DISABLE;
  hsd2.Init.ClockDiv = 0;
  if (HAL_SD_Init(&hsd2) != HAL_OK)
  {
    Error_Handler();
  }

}

static void MX_SPI1_Init(void)
{

  /* SPI1 parameter configuration*/
  hspi1.Instance = SPI1;
  hspi1.Init.Mode = SPI_MODE_MASTER;
  hspi1.Init.Direction = SPI_DIRECTION_2LINES;
  hspi1.Init.DataSize = SPI_DATASIZE_4BIT;
  hspi1.Init.CLKPolarity = SPI_POLARITY_LOW;
  hspi1.Init.CLKPhase = SPI_PHASE_1EDGE;
  hspi1.Init.NSS = SPI_NSS_SOFT;
  hspi1.Init.BaudRatePrescaler = SPI_BAUDRATEPRESCALER_2;
  hspi1.Init.FirstBit = SPI_FIRSTBIT_MSB;
  hspi1.Init.TIMode = SPI_TIMODE_DISABLE;
  hspi1.Init.CRCCalculation = SPI_CRCCALCULATION_DISABLE;
  hspi1.Init.CRCPolynomial = 0x0;
  hspi1.Init.NSSPMode = SPI_NSS_PULSE_ENABLE;
  hspi1.Init.NSSPolarity = SPI_NSS_POLARITY_LOW;
  hspi1.Init.FifoThreshold = SPI_FIFO_THRESHOLD_01DATA;
  hspi1.Init.TxCRCInitializationPattern = SPI_CRC_INITIALIZATION_ALL_ZERO_PATTERN;
  hspi1.Init.RxCRCInitializationPattern = SPI_CRC_INITIALIZATION_ALL_ZERO_PATTERN;
  hspi1.Init.MasterSSIdleness = SPI_MASTER_SS_IDLENESS_00CYCLE;
  hspi1.Init.MasterInterDataIdleness = SPI_MASTER_INTERDATA_IDLENESS_00CYCLE;
  hspi1.Init.MasterReceiverAutoSusp = SPI_MASTER_RX_AUTOSUSP_DISABLE;
  hspi1.Init.MasterKeepIOState = SPI_MASTER_KEEP_IO_STATE_DISABLE;
  hspi1.Init.IOSwap = SPI_IO_SWAP_DISABLE;
  if (HAL_SPI_Init(&hspi1) != HAL_OK)
  {
    Error_Handler();
  }

}

static void MX_SPI4_Init(void)
{

  /* SPI4 parameter configuration*/
  hspi4.Instance = SPI4;
  hspi4.Init.Mode = SPI_MODE_MASTER;
  hspi4.Init.Direction = SPI_DIRECTION_2LINES;
  hspi4.Init.DataSize = SPI_DATASIZE_4BIT;
  hspi4.Init.CLKPolarity = SPI_POLARITY_LOW;
  hspi4.Init.CLKPhase = SPI_PHASE_1EDGE;
  hspi4.Init.NSS = SPI_NSS_SOFT;
  hspi4.Init.BaudRatePrescaler = SPI_BAUDRATEPRESCALER_2;
  hspi4.Init.FirstBit = SPI_FIRSTBIT_MSB;
  hspi4.Init.TIMode = SPI_TIMODE_DISABLE;
  hspi4.Init.CRCCalculation = SPI_CRCCALCULATION_DISABLE;
  hspi4.Init.CRCPolynomial = 0x0;
  hspi4.Init.NSSPMode = SPI_NSS_PULSE_ENABLE;
  hspi4.Init.NSSPolarity = SPI_NSS_POLARITY_LOW;
  hspi4.Init.FifoThreshold = SPI_FIFO_THRESHOLD_01DATA;
  hspi4.Init.TxCRCInitializationPattern = SPI_CRC_INITIALIZATION_ALL_ZERO_PATTERN;
  hspi4.Init.RxCRCInitializationPattern = SPI_CRC_INITIALIZATION_ALL_ZERO_PATTERN;
  hspi4.Init.MasterSSIdleness = SPI_MASTER_SS_IDLENESS_00CYCLE;
  hspi4.Init.MasterInterDataIdleness = SPI_MASTER_INTERDATA_IDLENESS_00CYCLE;
  hspi4.Init.MasterReceiverAutoSusp = SPI_MASTER_RX_AUTOSUSP_DISABLE;
  hspi4.Init.MasterKeepIOState = SPI_MASTER_KEEP_IO_STATE_DISABLE;
  hspi4.Init.IOSwap = SPI_IO_SWAP_DISABLE;
  if (HAL_SPI_Init(&hspi4) != HAL_OK)
  {
    Error_Handler();
  }

}

static void MX_TIM5_Init(void)
{

  TIM_MasterConfigTypeDef sMasterConfig = {0};
  TIM_OC_InitTypeDef sConfigOC = {0};

  htim5.Instance = TIM5;
  htim5.Init.Prescaler = 0;
  htim5.Init.CounterMode = TIM_COUNTERMODE_UP;
  htim5.Init.Period = 4294967295;
  htim5.Init.ClockDivision = TIM_CLOCKDIVISION_DIV1;
  htim5.Init.AutoReloadPreload = TIM_AUTORELOAD_PRELOAD_DISABLE;
  if (HAL_TIM_PWM_Init(&htim5) != HAL_OK)
  {
    Error_Handler();
  }
  sMasterConfig.MasterOutputTrigger = TIM_TRGO_RESET;
  sMasterConfig.MasterSlaveMode = TIM_MASTERSLAVEMODE_DISABLE;
  if (HAL_TIMEx_MasterConfigSynchronization(&htim5, &sMasterConfig) != HAL_OK)
  {
    Error_Handler();
  }
  sConfigOC.OCMode = TIM_OCMODE_PWM1;
  sConfigOC.Pulse = 0;
  sConfigOC.OCPolarity = TIM_OCPOLARITY_HIGH;
  sConfigOC.OCFastMode = TIM_OCFAST_DISABLE;
  if (HAL_TIM_PWM_ConfigChannel(&htim5, &sConfigOC, TIM_CHANNEL_1) != HAL_OK)
  {
    Error_Handler();
  }
  HAL_TIM_MspPostInit(&htim5);

}

static void MX_UART4_Init(void)
{

  huart4.Instance = UART4;
  huart4.Init.BaudRate = 115200;
  huart4.Init.WordLength = UART_WORDLENGTH_8B;
  huart4.Init.StopBits = UART_STOPBITS_1;
  huart4.Init.Parity = UART_PARITY_NONE;
  huart4.Init.Mode = UART_MODE_TX_RX;
  huart4.Init.HwFlowCtl = UART_HWCONTROL_NONE;
  huart4.Init.OverSampling = UART_OVERSAMPLING_16;
  huart4.Init.OneBitSampling = UART_ONE_BIT_SAMPLE_DISABLE;
  huart4.Init.ClockPrescaler = UART_PRESCALER_DIV1;
  huart4.AdvancedInit.AdvFeatureInit = UART_ADVFEATURE_NO_INIT;
  if (HAL_UART_Init(&huart4) != HAL_OK)
  {
    Error_Handler();
  }
  if (HAL_UARTEx_SetTxFifoThreshold(&huart4, UART_TXFIFO_THRESHOLD_1_8) != HAL_OK)
  {
    Error_Handler();
  }
  if (HAL_UARTEx_SetRxFifoThreshold(&huart4, UART_RXFIFO_THRESHOLD_1_8) != HAL_OK)
  {
    Error_Handler();
  }
  if (HAL_UARTEx_DisableFifoMode(&huart4) != HAL_OK)
  {
    Error_Handler();
  }

}

static void MX_USART3_UART_Init(void)
{

  huart3.Instance = USART3;
  huart3.Init.BaudRate = 115200;
  huart3.Init.WordLength = UART_WORDLENGTH_8B;
  huart3.Init.StopBits = UART_STOPBITS_1;
  huart3.Init.Parity = UART_PARITY_NONE;
  huart3.Init.Mode = UART_MODE_TX_RX;
  huart3.Init.HwFlowCtl = UART_HWCONTROL_RTS_CTS;
  huart3.Init.OverSampling = UART_OVERSAMPLING_16;
  huart3.Init.OneBitSampling = UART_ONE_BIT_SAMPLE_DISABLE;
  huart3.Init.ClockPrescaler = UART_PRESCALER_DIV1;
  huart3.AdvancedInit.AdvFeatureInit = UART_ADVFEATURE_NO_INIT;
  if (HAL_UART_Init(&huart3) != HAL_OK)
  {
    Error_Handler();
  }
  if (HAL_UARTEx_SetTxFifoThreshold(&huart3, UART_TXFIFO_THRESHOLD_1_8) != HAL_OK)
  {
    Error_Handler();
  }
  if (HAL_UARTEx_SetRxFifoThreshold(&huart3, UART_RXFIFO_THRESHOLD_1_8) != HAL_OK)
  {
    Error_Handler();
  }
  if (HAL_UARTEx_DisableFifoMode(&huart3) != HAL_OK)
  {
    Error_Handler();
  }

}

static void MX_USB_OTG_FS_PCD_Init(void)
{

  hpcd_USB_OTG_FS.Instance = USB_OTG_FS;
  hpcd_USB_OTG_FS.Init.dev_endpoints = 9;
  hpcd_USB_OTG_FS.Init.speed = PCD_SPEED_FULL;
  hpcd_USB_OTG_FS.Init.dma_enable = DISABLE;
  hpcd_USB_OTG_FS.Init.phy_itface = PCD_PHY_EMBEDDED;
  hpcd_USB_OTG_FS.Init.Sof_enable = DISABLE;
  hpcd_USB_OTG_FS.Init.low_power_enable = DISABLE;
  hpcd_USB_OTG_FS.Init.lpm_enable = DISABLE;
  hpcd_USB_OTG_FS.Init.battery_charging_enable = DISABLE;
  hpcd_USB_OTG_FS.Init.vbus_sensing_enable = DISABLE;
  hpcd_USB_OTG_FS.Init.use_dedicated_ep1 = DISABLE;
  if (HAL_PCD_Init(&hpcd_USB_OTG_FS) != HAL_OK)
  {
    Error_Handler();
  }

}

/* FMC initialization function */
static void MX_FMC_Init(void)
{

  FMC_SDRAM_TimingTypeDef SdramTiming = {0};

  /** Perform the SDRAM1 memory initialization sequence
  */
  hsdram1.Instance = FMC_SDRAM_DEVICE;
  /* hsdram1.Init */
  hsdram1.Init.SDBank = FMC_SDRAM_BANK1;
  hsdram1.Init.ColumnBitsNumber = FMC_SDRAM_COLUMN_BITS_NUM_8;
  hsdram1.Init.RowBitsNumber = FMC_SDRAM_ROW_BITS_NUM_13;
  hsdram1.Init.MemoryDataWidth = FMC_SDRAM_MEM_BUS_WIDTH_16;
  hsdram1.Init.InternalBankNumber = FMC_SDRAM_INTERN_BANKS_NUM_4;
  hsdram1.Init.CASLatency = FMC_SDRAM_CAS_LATENCY_1;
  hsdram1.Init.WriteProtection = FMC_SDRAM_WRITE_PROTECTION_DISABLE;
  hsdram1.Init.SDClockPeriod = FMC_SDRAM_CLOCK_DISABLE;
  hsdram1.Init.ReadBurst = FMC_SDRAM_RBURST_DISABLE;
  hsdram1.Init.ReadPipeDelay = FMC_SDRAM_RPIPE_DELAY_0;
  /* SdramTiming */
  SdramTiming.LoadToActiveDelay = 16;
  SdramTiming.ExitSelfRefreshDelay = 16;
  SdramTiming.SelfRefreshTime = 16;
  SdramTiming.RowCycleDelay = 16;
  SdramTiming.WriteRecoveryTime = 16;
  SdramTiming.RPDelay = 16;
  SdramTiming.RCDDelay = 16;

  if (HAL_SDRAM_Init(&hsdram1, &SdramTiming) != HAL_OK)
  {
    Error_Handler( );
  }

}

static void MX_GPIO_Init(void)
{
  GPIO_InitTypeDef GPIO_InitStruct = {0};

  /* GPIO Ports Clock Enable */
  __HAL_RCC_GPIOB_CLK_ENABLE();
  __HAL_RCC_GPIOK_CLK_ENABLE();
  __HAL_RCC_GPIOG_CLK_ENABLE();
  __HAL_RCC_GPIOC_CLK_ENABLE();
  __HAL_RCC_GPIOE_CLK_ENABLE();
  __HAL_RCC_GPIOJ_CLK_ENABLE();
  __HAL_RCC_GPIOD_CLK_ENABLE();
  __HAL_RCC_GPIOI_CLK_ENABLE();
  __HAL_RCC_GPIOA_CLK_ENABLE();
  __HAL_RCC_GPIOF_CLK_ENABLE();
  __HAL_RCC_GPIOH_CLK_ENABLE();

  /*Configure GPIO pins : PG11 PG14 */
  GPIO_InitStruct.Pin = GPIO_PIN_11|GPIO_PIN_14;
  GPIO_InitStruct.Mode = GPIO_MODE_AF_PP;
  GPIO_InitStruct.Pull = GPIO_NOPULL;
  GPIO_InitStruct.Speed = GPIO_SPEED_FREQ_VERY_HIGH;
  GPIO_InitStruct.Alternate = GPIO_AF11_ETH;
  HAL_GPIO_Init(GPIOG, &GPIO_InitStruct);

}

void Error_Handler(void)
{
}
